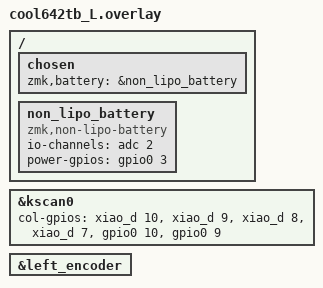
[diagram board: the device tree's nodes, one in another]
#include "cool642tb.dtsi"

/ {
    chosen {
        zmk,battery = &non_lipo_battery;
    };

    non_lipo_battery: non_lipo_battery {
        compatible = "zmk,non-lipo-battery";
        io-channels = <&adc 2>;  // 使用するADCチャンネル
        
        // オプション: 電圧分圧器の電源制御GPIO
        power-gpios = <&gpio0 3 GPIO_ACTIVE_HIGH>;  // 使用するGPIOに置き換えてください
    };
};

&kscan0 {
        col-gpios
            = <&xiao_d 10 GPIO_ACTIVE_HIGH>
            , <&xiao_d 9 GPIO_ACTIVE_HIGH> 
            , <&xiao_d 8 GPIO_ACTIVE_HIGH> 
            , <&xiao_d 7 GPIO_ACTIVE_HIGH> 
            , <&gpio0 10 GPIO_ACTIVE_HIGH>
            , <&gpio0 9 GPIO_ACTIVE_HIGH>
            ;
};

&left_encoder {
    status = "okay";
};
